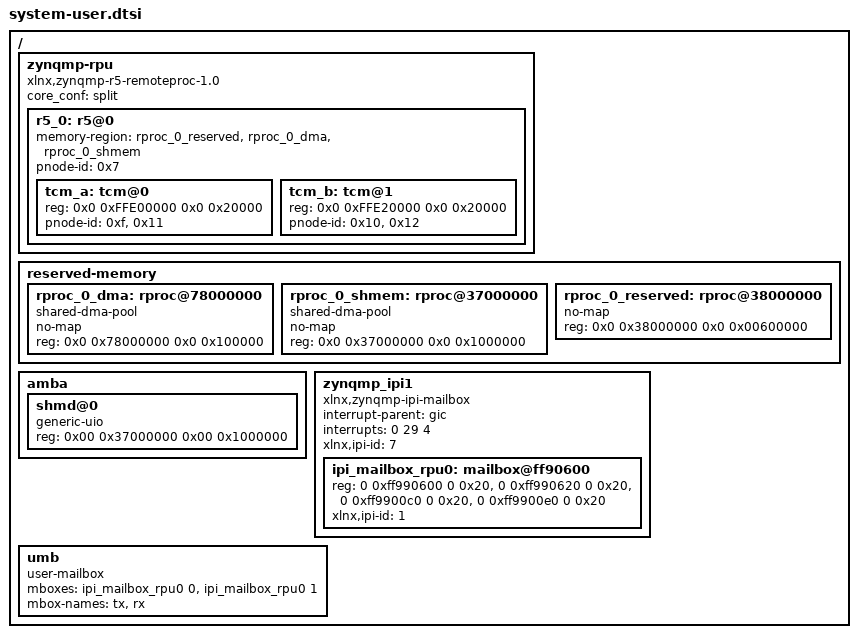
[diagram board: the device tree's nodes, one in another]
/ {

        zynqmp-rpu {
                compatible = "xlnx,zynqmp-r5-remoteproc-1.0";
                #address-cells = <2>;
                #size-cells = <2>;
                ranges;
                core_conf = "split";
                r5_0: r5@0 {
                        #address-cells = <2>;
                        #size-cells = <2>;
                        ranges;
                        memory-region = <&rproc_0_reserved>, <&rproc_0_dma>, <&rproc_0_shmem>;
                        pnode-id = <0x7>;
                        tcm_a: tcm@0 {
                                reg = <0x0 0xFFE00000 0x0 0x20000>;
                                pnode-id = <0xf>, <0x11>;
                        };
                        tcm_b: tcm@1 {
                                reg = <0x0 0xFFE20000 0x0 0x20000>;
                                pnode-id = <0x10>, <0x12>;
                        };
                };
        };

        reserved-memory {
                #address-cells = <2>;
                #size-cells = <2>;
                ranges;
                rproc_0_dma: rproc@78000000 {
                        no-map;
                        compatible = "shared-dma-pool";
                        reg = <0x0 0x78000000 0x0 0x100000>;
                };
                rproc_0_shmem: rproc@37000000 {
                        no-map;
                        compatible = "shared-dma-pool";
                        reg = <0x0 0x37000000 0x0 0x1000000>;
                };
                /* Memory for R5 firmware in DDR */
                rproc_0_reserved: rproc@38000000 {
                        no-map;
                        reg = <0x0 0x38000000 0x0 0x00600000>;
                };
		};
		amba {
			/* shared memory */
			shmd@0 {
				/*no-map;*/
				compatible = "generic-uio";
				reg = <0x00 0x37000000 0x00 0x1000000>;
			};
        };

   zynqmp_ipi1 {
        compatible = "xlnx,zynqmp-ipi-mailbox";
        interrupt-parent = <&gic>;
        interrupts = <0 29 4>;
        xlnx,ipi-id = <7>;
        #address-cells = <2>;
        #size-cells = <2>;
        ranges;
  
        /* APU<->RPU0 IPI mailbox controller */
        ipi_mailbox_rpu0: mailbox@ff90600 {
            reg = <0 0xff990600 0 0x20>,
                  <0 0xff990620 0 0x20>,
                  <0 0xff9900c0 0 0x20>,
                  <0 0xff9900e0 0 0x20>;
            reg-names = "local_request_region",
                    "local_response_region",
                    "remote_request_region",
                    "remote_response_region";
            #mbox-cells = <1>;
            xlnx,ipi-id = <1>;
        };
    };

    umb {
    compatible = "user-mailbox";
    mboxes = <&ipi_mailbox_rpu0 0>, <&ipi_mailbox_rpu0 1>;
    mbox-names = "tx", "rx";
    };
};
